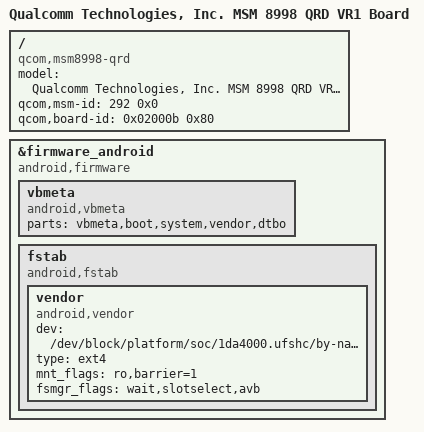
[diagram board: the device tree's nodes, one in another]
/* Copyright (c) 2017, The Linux Foundation. All rights reserved.
 *
 * This program is free software; you can redistribute it and/or modify
 * it under the terms of the GNU General Public License version 2 and
 * only version 2 as published by the Free Software Foundation.
 *
 * This program is distributed in the hope that it will be useful,
 * but WITHOUT ANY WARRANTY; without even the implied warranty of
 * MERCHANTABILITY or FITNESS FOR A PARTICULAR PURPOSE.  See the
 * GNU General Public License for more details.
 */


/dts-v1/;
/plugin/;

#include <dt-bindings/clock/msm-clocks-8998.h>
#include <dt-bindings/interrupt-controller/irq.h>

#include "msm8998-qrd-vr1.dtsi"
#include "msm8998-qrd-audio-overlay.dtsi"

/ {
	model = "Qualcomm Technologies, Inc. MSM 8998 QRD VR1 Board";
	compatible = "qcom,msm8998-qrd", "qcom,msm8998", "qcom,qrd";
	qcom,msm-id = <292 0x0>;
	qcom,board-id = <0x02000b 0x80>;
};

&firmware_android {
	compatible = "android,firmware";
	vbmeta {
		compatible = "android,vbmeta";
		parts = "vbmeta,boot,system,vendor,dtbo";
	};
	fstab {
		compatible = "android,fstab";
		vendor {
			compatible = "android,vendor";
			dev = "/dev/block/platform/soc/1da4000.ufshc/by-name/vendor";
			type = "ext4";
			mnt_flags = "ro,barrier=1";
			fsmgr_flags = "wait,slotselect,avb";
		};
	};
};
